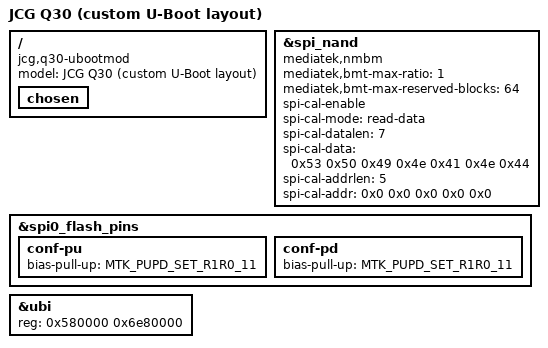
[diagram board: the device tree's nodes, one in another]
// SPDX-License-Identifier: GPL-2.0-or-later OR MIT
/*
 * JCG Q30 / Q30 PRO (custom U-Boot layout)
 *
 * openwrt-25.12 port of the 24.10 ubootmod DTS (itself ported from
 * the ImmortalWrt openwrt-23.05 mt7981b-jcg-q30-ubootmod.dts).
 * The vendor "unbrickable" U-Boot (kept in the "fip" partition) boots a
 * FIT image from the "kernel" UBI volume and keeps its environment in
 * the "u-boot-env" MTD partition, so this variant keeps the classic
 * kernel/rootfs/rootfs_data UBI layout instead of the single "fit"
 * volume used by the OpenWrt U-Boot layout.
 *
 * 25.12 notes:
 *  - stock partition table is unchanged vs 24.10
 *  - base dtsi "mt7981b.dtsi" is generated by kernel patch
 *    117-complete-mt7981b-dtsi.patch
 *  - spi pin config moved from mediatek,pull-up-adv to standard
 *    "bias" properties, so the pull-up override clears "bias" first
 *
 * Copyright (C) 2023 Tianling Shen <cnsztl@immortalwrt.org>
 */

/dts-v1/;
#include <dt-bindings/pinctrl/mt65xx.h>

#include "mt7981b-jcg-q30-pro.dts"

/ {
	model = "JCG Q30 (custom U-Boot layout)";

	compatible = "jcg,q30-ubootmod", "mediatek,mt7981";

	/* The vendor U-Boot environment carries the bootargs
	 * (root=/dev/ubiblock0_x rootfstype=squashfs); do not force
	 * the OpenWrt U-Boot layout's "root=/dev/fit0" here.
	 */
	chosen {
		/delete-property/ bootargs-append;
		/delete-property/ rootdisk;
	};
};

&spi_nand {
	/* The 6.12 MTK_BMT module provides NMBM remapping; the
	 * bmt-max-* tuning properties are kept as in the 23.05 /
	 * 24.10 ubootmod DTS.
	 */
	mediatek,nmbm;
	mediatek,bmt-max-ratio = <1>;
	mediatek,bmt-max-reserved-blocks = <64>;

	spi-cal-enable;
	spi-cal-mode = "read-data";
	spi-cal-datalen = <7>;
	spi-cal-data = /bits/ 8 <0x53 0x50 0x49 0x4e 0x41 0x4e 0x44>;
	spi-cal-addrlen = <5>;
	spi-cal-addr = /bits/ 32 <0x0 0x0 0x0 0x0 0x0>;
};

&spi0_flash_pins {
	conf-pu {
		/delete-property/ bias;
		bias-pull-up = <MTK_PUPD_SET_R1R0_11>;
	};

	conf-pd {
		/delete-property/ bias;
		bias-pull-up = <MTK_PUPD_SET_R1R0_11>;
	};
};

&ubi {
	/* Vendor U-Boot scans the UBI partition with the stock
	 * geometry; keep the 23.05 / 24.10 ubootmod size.
	 */
	reg = <0x580000 0x6e80000>;

	/delete-node/ volumes;
};
